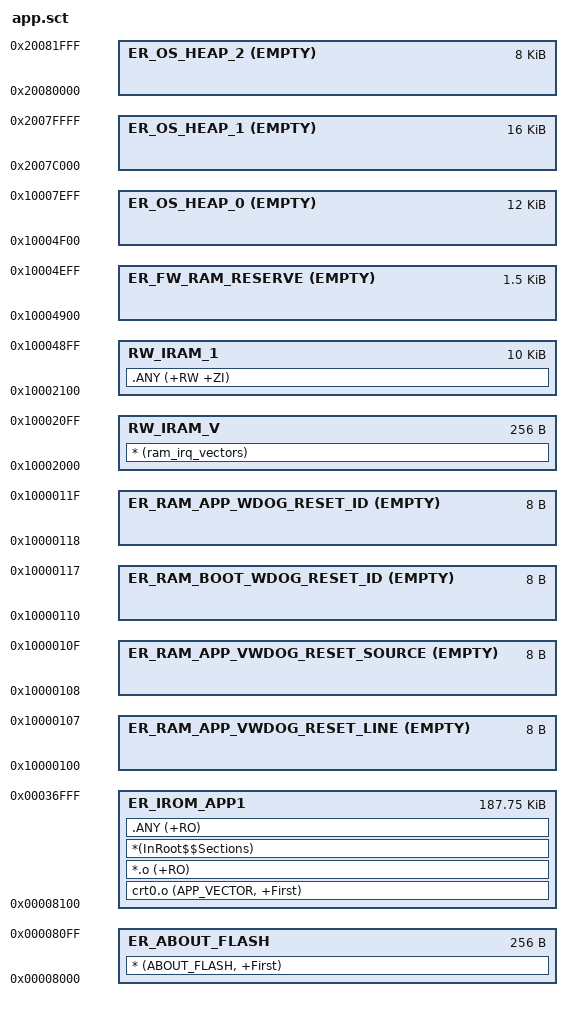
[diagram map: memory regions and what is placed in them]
; *************************************************************
; *** Scatter-Loading Description File generated by uVision ***
; ************************************************************* 

;-----------------------------------------------------------------------------;

LR_ABOUT                  0x00008000        0x100
{
  ER_ABOUT_FLASH          0x00008000 0x100  ;
    {
      * (ABOUT_FLASH, +First)
    }
}

;----------------------------------------------------------------------------;

; DS4 split policy: the CORE code region is HARD-CAPPED at the ABI info addr 0x37000
; (size 0x2EF00 = 0x37000 - 0x8100). CORE code must fit below the shared ABI info /
; API table (0x37000 / 0x37040); the FW image lives at 0x38000..0x3FEFF. Growing CORE
; past 0x37000 is a LINK error (region overflow) -- never a silent overlap with the
; table or FW. Keep in sync with core_contract_ds4_image_layout.h.
LR_IROM_APP1 0x00008100 0x0002EF00
{    ; load region size_region
  ER_IROM_APP1 0x8100   0x0002EF00
    {
      crt0.o (APP_VECTOR, +First) 
      *.o (+RO) 
      *(InRoot$$Sections)
      .ANY (+RO)
    }


  ER_RAM_APP_VWDOG_RESET_LINE    0x10000100 EMPTY    0x08       ; On-Chip   : VWDOG APP Reset source line number
    {
      
    }

  ER_RAM_APP_VWDOG_RESET_SOURCE  0x10000108 EMPTY    0x08       ; On-Chip   : VWDOG APP Reset source
    {
      
    }
  ER_RAM_BOOT_WDOG_RESET_ID      0x10000110 EMPTY    0x08       ; On-Chip   : WDOG BOOT Reset identification code
    {
      
    }

  ER_RAM_APP_WDOG_RESET_ID       0x10000118 EMPTY    0x08       ; On-Chip   : WDOG APP Reset identification code
    {
      
    }


;----------------------------------------------------------------------------;

; memory reserved for Boot persistant memory and NVRAM cache 0x10000120 - 0x10002000

;----------------------------------------------------------------------------;



  RW_IRAM_V 0x10002000 0x00000100 ; RAM : On-Chip
    {
		* (ram_irq_vectors)
    }

  RW_IRAM_1 0x10002100 (0x00004900 - 0x2100) ; RAM : On-Chip  (= 0x2800, shrunk 0x600 to reserve FW RAM)
    {
		.ANY (+RW +ZI)
    }

  ; DS4 thin-FW RW/ZI window (DS5). CORE must NOT place RW/ZI here; the thin FW's
  ; scatter (app_fw_ds4_thin.sct) puts RW_FW at exactly 0x10004900 size 0x600 so
  ; fw_ram_init can memcpy/memset it. Sized from measured vehicle RW+ZI (F=0x471)
  ; + growth headroom. Keep base+size in sync with the FW scatter.
  ER_FW_RAM_RESERVE      0x10004900 EMPTY  0x600      ; RW_FW window (CORE-reserved)
    {
    }

  ER_OS_HEAP_0           0x10004F00 EMPTY  0x3000     ; On chip : Heap 0 sections
    {
    }

;----------------------------------------------------------------------------;

; memory reserved for IAP command 0x10007F00 - 0x10007FFF

;----------------------------------------------------------------------------;


  ER_OS_HEAP_1           0x2007C000 EMPTY  0x00004000  ; On chip : Heap 1 sections
    {
    }
  
  ER_OS_HEAP_2           0x20080000 EMPTY  0x00002000  ; On chip : Heap 2 sections, the rest 4K was reserved/used by bootloader
    { 
    }
}
